# MEMCFG_0.5 register map
Vendor: Texas Instruments
Peripheral module from a debugger description file (folder mspm33c321x).
Registers are 32-bit, read-write, no defined reset value unless marked. A register's access mark holds for its fields unless they carry their own. Offsets are as the file gives them; lines under a group give offsets from that group; [hi:lo] are bit positions; {n}, {i} and the like mark numbered series; 'fields as' and 'values as' point back to an identical list; <NAME> marks a mode.

## MEMCFG
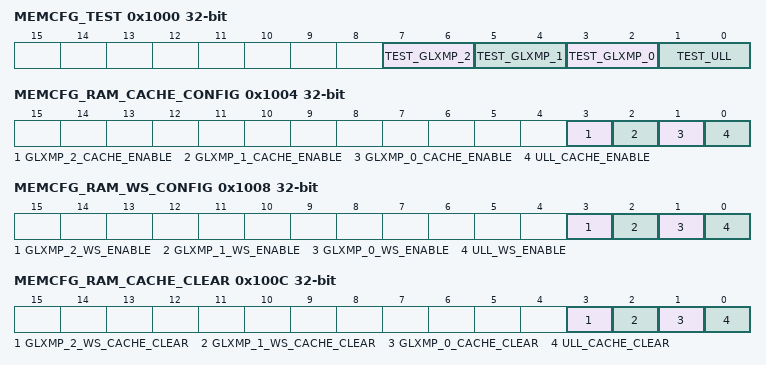
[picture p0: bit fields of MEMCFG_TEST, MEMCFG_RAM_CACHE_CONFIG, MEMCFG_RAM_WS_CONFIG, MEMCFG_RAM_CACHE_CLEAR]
0x1000 MEMCFG_TEST — RAM TEST Register
  [7:6] TEST_GLXMP_2 — Selects the defferent modes for GLXMP_2 RAM: #br# 00: Functional Mode. #br# 01: Writes are allowed to data bits only. No write to ECC bits. #br# 10: Writes are allowed to ECC bits only. No write to data bits. #br# 11: Same as functional mode
  [5:4] TEST_GLXMP_1 — Selects the defferent modes for GLXMP_1 RAM: #br# 00: Functional Mode. #br# 01: Writes are allowed to data bits only. No write to ECC bits. #br# 10: Writes are allowed to ECC bits only. No write to data bits. #br# 11: Same as functional mode
  [3:2] TEST_GLXMP_0 — Selects the defferent modes for GLXMP_0 RAM: #br# 00: Functional Mode. #br# 01: Writes are allowed to data bits only. No write to ECC bits. #br# 10: Writes are allowed to ECC bits only. No write to data bits. #br# 11: Same as functional mode
  [1:0] TEST_ULL — Selects the defferent modes for ULL RAM: #br# 00: Functional Mode. #br# 01: Writes are allowed to data bits only. No write to ECC bits. #br# 10: Writes are allowed to ECC bits only. No write to data bits. #br# 11: Same as functional mode
0x1004 MEMCFG_RAM_CACHE_CONFIG — RAM CACHE configuration
  [3] GLXMP_2_CACHE_ENABLE — Cache configuration for GLXMP_2 RAM: #br# 1: Cache enable. #br# 0: Cache support disable.
  [2] GLXMP_1_CACHE_ENABLE — Cache configuration for GLXMP_1 RAM: #br# 1: Cache enable. #br# 0: Cache support disable.
  [1] GLXMP_0_CACHE_ENABLE — Cache configuration for GLXMP_0 RAM: #br# 1: Cache enable. #br# 0: Cache support disable.
  [0] ULL_CACHE_ENABLE — Cache configuration for ULL RAM: #br# 1: Cache enable. #br# 0: Cache support disable.
0x1008 MEMCFG_RAM_WS_CONFIG — RAM wait state configuration
  [3] GLXMP_2_WS_ENABLE — Wait state configuration for GLXMP_2 RAM: #br# 0: 1wait state disable. #br# 1: 1 wait enable.
  [2] GLXMP_1_WS_ENABLE — Wait state configuration for GLXMP_1 RAM: #br# 0: 1wait state disable. #br# 1: 1 wait enable.
  [1] GLXMP_0_WS_ENABLE — Wait state configuration for GLXMP_0 RAM: #br# 0: 1wait state disable. #br# 1: 1 wait enable.
  [0] ULL_WS_ENABLE — Wait state configuration for ULL RAM: #br# 0: 1wait state disable. #br# 1: 1 wait enable.
0x100C MEMCFG_RAM_CACHE_CLEAR — RAM cache clear
  [3] GLXMP_2_WS_CACHE_CLEAR — Cache clear configuration for GLXMP_2 RAM: #br# 0: wont clear the cache valid slots. #br# 1: Clear the all cache valid slots and write back the write buffer data to memory macro.
  [2] GLXMP_1_WS_CACHE_CLEAR — Cache clear configuration for GLXMP_1 RAM: #br# 0: wont clear the cache valid slots. #br# 1: Clear the all cache valid slots and write back the write buffer data to memory macro.
  [1] GLXMP_0_CACHE_CLEAR — Cache clear configuration for GLAMP_0 RAM: #br# 0: wont clear the cache valid slots. #br# 1: Clear the all cache valid slots and write back the write buffer data to memory macro.
  [0] ULL_CACHE_CLEAR — Cache clear configuration for ULL RAM: #br# 0: wont clear the cache valid slots. #br# 1: Clear the all cache valid slots and write back the write buffer data to memory macro.
0x1010 MEMCFG_ROM_WS_CONFIG — ROM wait state configuration
  [0] ROM_WS_ENABLE — Wait state configuration ROM: #br# 0: 1wait state disable. #br# 1: 1 wait enable.
